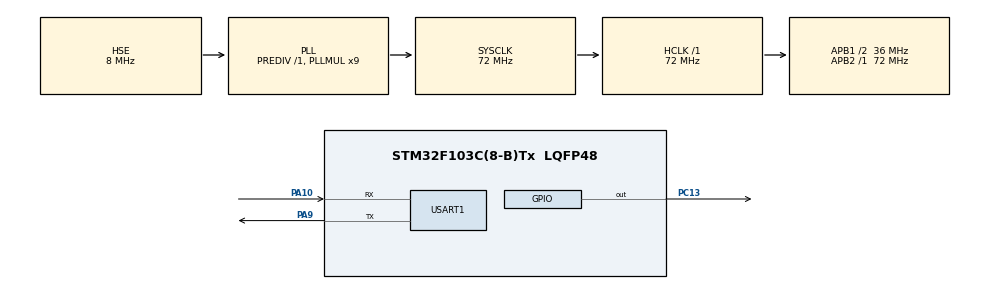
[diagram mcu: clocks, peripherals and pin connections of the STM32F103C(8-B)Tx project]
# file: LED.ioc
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Dma.Request0=USART1_TX
Dma.Request1=USART1_RX
Dma.USART1_RX.1.Direction=DMA_PERIPH_TO_MEMORY
Dma.USART1_RX.1.Instance=DMA1_Channel5
Dma.USART1_RX.1.MemDataAlignment=DMA_MDATAALIGN_BYTE
Dma.USART1_RX.1.MemInc=DMA_MINC_ENABLE
Dma.USART1_RX.1.Mode=DMA_NORMAL
Dma.USART1_RX.1.PeriphDataAlignment=DMA_PDATAALIGN_BYTE
Dma.USART1_RX.1.PeriphInc=DMA_PINC_DISABLE
Dma.USART1_RX.1.Priority=DMA_PRIORITY_LOW
Dma.USART1_TX.0.Direction=DMA_MEMORY_TO_PERIPH
Dma.USART1_TX.0.Instance=DMA1_Channel4
Dma.USART1_TX.0.MemDataAlignment=DMA_MDATAALIGN_BYTE
Dma.USART1_TX.0.MemInc=DMA_MINC_ENABLE
Dma.USART1_TX.0.Mode=DMA_NORMAL
Dma.USART1_TX.0.PeriphDataAlignment=DMA_PDATAALIGN_BYTE
Dma.USART1_TX.0.PeriphInc=DMA_PINC_DISABLE
Dma.USART1_TX.0.Priority=DMA_PRIORITY_LOW
Mcu.Family=STM32F1
Mcu.Name=STM32F103C(8-B)Tx
Mcu.Package=LQFP48
NVIC.DMA1_Channel4_IRQn=true\:0\:0\:false\:false\:true\:false
NVIC.DMA1_Channel5_IRQn=true\:0\:0\:false\:false\:true\:false
NVIC.PriorityGroup=NVIC_PRIORITYGROUP_4
NVIC.TIM1_UP_IRQn=true\:0\:0\:false\:false\:true\:true
NVIC.USART1_IRQn=true\:0\:0\:false\:false\:true\:true
PA10.Mode=Asynchronous
PA10.Signal=USART1_RX
PA13.Mode=Serial_Wire
PA13.Signal=SYS_JTMS-SWDIO
PA14.Mode=Serial_Wire
PA14.Signal=SYS_JTCK-SWCLK
PA9.Mode=Asynchronous
PA9.Signal=USART1_TX
PC13-TAMPER-RTC.Signal=GPIO_Output
PD0-OSC_IN.Mode=HSE-External-Oscillator
PD0-OSC_IN.Signal=RCC_OSC_IN
PD1-OSC_OUT.Mode=HSE-External-Oscillator
PD1-OSC_OUT.Signal=RCC_OSC_OUT
ProjectManager.HeapSize=0x200
ProjectManager.StackSize=0x400
ProjectManager.TargetToolchain=MDK-ARM V5
RCC.AHBFreq_Value=72000000
RCC.APB1CLKDivider=RCC_HCLK_DIV2
RCC.APB1Freq_Value=36000000
RCC.APB1TimFreq_Value=72000000
RCC.APB2Freq_Value=72000000
RCC.APB2TimFreq_Value=72000000
RCC.HCLKFreq_Value=72000000
RCC.PLLMUL=RCC_PLL_MUL9
RCC.PLLSourceVirtual=RCC_PLLSOURCE_HSE
RCC.SYSCLKFreq_VALUE=72000000
RCC.SYSCLKSource=RCC_SYSCLKSOURCE_PLLCLK
RCC.USBFreq_Value=72000000
TIM1.AutoReloadPreload=TIM_AUTORELOAD_PRELOAD_ENABLE
TIM1.Period=5000-1
TIM1.Prescaler=7200-1
USART1.VirtualMode=VM_ASYNC
VP_TIM1_VS_ClockSourceINT.Mode=Internal
board=custom

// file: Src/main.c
/**
  ******************************************************************************
  * @file           : main.c
  * @brief          : Main program body
  ******************************************************************************
  ** This notice applies to any and all portions of this file
  * that are not between comment pairs USER CODE BEGIN and
  * USER CODE END. Other portions of this file, whether
  * inserted by the user or by software development tools
  * are owned by their respective copyright owners.
  *
  * COPYRIGHT(c) 2018 STMicroelectronics
  *
  * Redistribution and use in source and binary forms, with or without modification,
  * are permitted provided that the following conditions are met:
  *   1. Redistributions of source code must retain the above copyright notice,
  *      this list of conditions and the following disclaimer.
  *   2. Redistributions in binary form must reproduce the above copyright notice,
  *      this list of conditions and the following disclaimer in the documentation
  *      and/or other materials provided with the distribution.
  *   3. Neither the name of STMicroelectronics nor the names of its contributors
  *      may be used to endorse or promote products derived from this software
  *      without specific prior written permission.
  *
  * THIS SOFTWARE IS PROVIDED BY THE COPYRIGHT HOLDERS AND CONTRIBUTORS "AS IS"
  * AND ANY EXPRESS OR IMPLIED WARRANTIES, INCLUDING, BUT NOT LIMITED TO, THE
  * IMPLIED WARRANTIES OF MERCHANTABILITY AND FITNESS FOR A PARTICULAR PURPOSE ARE
  * DISCLAIMED. IN NO EVENT SHALL THE COPYRIGHT HOLDER OR CONTRIBUTORS BE LIABLE
  * FOR ANY DIRECT, INDIRECT, INCIDENTAL, SPECIAL, EXEMPLARY, OR CONSEQUENTIAL
  * DAMAGES (INCLUDING, BUT NOT LIMITED TO, PROCUREMENT OF SUBSTITUTE GOODS OR
  * SERVICES; LOSS OF USE, DATA, OR PROFITS; OR BUSINESS INTERRUPTION) HOWEVER
  * CAUSED AND ON ANY THEORY OF LIABILITY, WHETHER IN CONTRACT, STRICT LIABILITY,
  * OR TORT (INCLUDING NEGLIGENCE OR OTHERWISE) ARISING IN ANY WAY OUT OF THE USE
  * OF THIS SOFTWARE, EVEN IF ADVISED OF THE POSSIBILITY OF SUCH DAMAGE.
  *
  ******************************************************************************
  */
#include "main.h"
#include "stm32f1xx_hal.h"
#include "string.h"

TIM_HandleTypeDef htim1;

UART_HandleTypeDef huart1;
DMA_HandleTypeDef hdma_usart1_tx;
DMA_HandleTypeDef hdma_usart1_rx;

/* USER CODE BEGIN PV */
/* Private variables ---------------------------------------------------------*/
#ifdef __GNUC__
/* With GCC/RAISONANCE, small printf (option LD Linker->Libraries->Small printf
   set to 'Yes') calls __io_putchar() */
#define PUTCHAR_PROTOTYPE int __io_putchar(int ch)
#else
#define PUTCHAR_PROTOTYPE int fputc(int ch, FILE *f)
#endif /* __GNUC__ */

PUTCHAR_PROTOTYPE
{
  /* Place your implementation of fputc here */
  /* e.g. write a character to the USART1 and Loop until the end of transmission */
  HAL_UART_Transmit(&huart1, (uint8_t *)&ch, 1, 0xFFFF);
  return ch;
}

/* USER CODE END PV */

void SystemClock_Config(void);
static void MX_GPIO_Init(void);
static void MX_DMA_Init(void);
static void MX_TIM1_Init(void);
static void MX_USART1_UART_Init(void);

/* USER CODE BEGIN PFP */
/* Private function prototypes -----------------------------------------------*/

/* USER CODE END PFP */

int main(void)
{

  /* MCU Configuration----------------------------------------------------------*/

  /* Reset of all peripherals, Initializes the Flash interface and the Systick. */
  HAL_Init();

  /* Configure the system clock */
  SystemClock_Config();

  /* Initialize all configured peripherals */
  MX_GPIO_Init();
  MX_DMA_Init();
  MX_TIM1_Init();
  MX_USART1_UART_Init();
  /* USER CODE BEGIN 2 */
  /*开启串口空闲中断*/
  __HAL_UART_ENABLE_IT(&huart1, UART_IT_IDLE);

    /*启动串口DMA接收*/
  HAL_UART_Receive_DMA(&huart1,rx_buffer,BUFFER_SIZE);
  HAL_TIM_Base_Start_IT(&htim1);
  printf("init ok \r\n");
  /* USER CODE END 2 */

  /* Infinite loop */
  while (1)
  {
    if(recv_end_flag ==1)
    {
        rx_len=0;
        recv_end_flag=0;
        if(strcmp((char*)rx_buffer,"LED") == 0) HAL_GPIO_TogglePin(GPIOC,GPIO_PIN_13);
//        HAL_UART_Transmit_DMA(&huart1,rx_buffer,rx_len);
//        HAL_UART_Receive_DMA(&huart1,rx_buffer,BUFFER_SIZE);
    }
  }

}

void SystemClock_Config(void)
{

  RCC_OscInitTypeDef RCC_OscInitStruct;
  RCC_ClkInitTypeDef RCC_ClkInitStruct;

    /**Initializes the CPU, AHB and APB busses clocks
    */
  RCC_OscInitStruct.OscillatorType = RCC_OSCILLATORTYPE_HSE;
  RCC_OscInitStruct.HSEState = RCC_HSE_ON;
  RCC_OscInitStruct.HSEPredivValue = RCC_HSE_PREDIV_DIV1;
  RCC_OscInitStruct.HSIState = RCC_HSI_ON;
  RCC_OscInitStruct.PLL.PLLState = RCC_PLL_ON;
  RCC_OscInitStruct.PLL.PLLSource = RCC_PLLSOURCE_HSE;
  RCC_OscInitStruct.PLL.PLLMUL = RCC_PLL_MUL9;
  if (HAL_RCC_OscConfig(&RCC_OscInitStruct) != HAL_OK)
  {
    _Error_Handler(__FILE__, __LINE__);
  }

    /**Initializes the CPU, AHB and APB busses clocks
    */
  RCC_ClkInitStruct.ClockType = RCC_CLOCKTYPE_HCLK|RCC_CLOCKTYPE_SYSCLK
                              |RCC_CLOCKTYPE_PCLK1|RCC_CLOCKTYPE_PCLK2;
  RCC_ClkInitStruct.SYSCLKSource = RCC_SYSCLKSOURCE_PLLCLK;
  RCC_ClkInitStruct.AHBCLKDivider = RCC_SYSCLK_DIV1;
  RCC_ClkInitStruct.APB1CLKDivider = RCC_HCLK_DIV2;
  RCC_ClkInitStruct.APB2CLKDivider = RCC_HCLK_DIV1;

  if (HAL_RCC_ClockConfig(&RCC_ClkInitStruct, FLASH_LATENCY_2) != HAL_OK)
  {
    _Error_Handler(__FILE__, __LINE__);
  }

    /**Configure the Systick interrupt time
    */
  HAL_SYSTICK_Config(HAL_RCC_GetHCLKFreq()/1000);

    /**Configure the Systick
    */
  HAL_SYSTICK_CLKSourceConfig(SYSTICK_CLKSOURCE_HCLK);

  /* SysTick_IRQn interrupt configuration */
  HAL_NVIC_SetPriority(SysTick_IRQn, 0, 0);
}

/* TIM1 init function */
static void MX_TIM1_Init(void)
{

  TIM_ClockConfigTypeDef sClockSourceConfig;
  TIM_MasterConfigTypeDef sMasterConfig;

  htim1.Instance = TIM1;
  htim1.Init.Prescaler = 7200-1;
  htim1.Init.CounterMode = TIM_COUNTERMODE_UP;
  htim1.Init.Period = 5000-1;
  htim1.Init.ClockDivision = TIM_CLOCKDIVISION_DIV1;
  htim1.Init.RepetitionCounter = 0;
  htim1.Init.AutoReloadPreload = TIM_AUTORELOAD_PRELOAD_ENABLE;
  if (HAL_TIM_Base_Init(&htim1) != HAL_OK)
  {
    _Error_Handler(__FILE__, __LINE__);
  }

  sClockSourceConfig.ClockSource = TIM_CLOCKSOURCE_INTERNAL;
  if (HAL_TIM_ConfigClockSource(&htim1, &sClockSourceConfig) != HAL_OK)
  {
    _Error_Handler(__FILE__, __LINE__);
  }

  sMasterConfig.MasterOutputTrigger = TIM_TRGO_RESET;
  sMasterConfig.MasterSlaveMode = TIM_MASTERSLAVEMODE_DISABLE;
  if (HAL_TIMEx_MasterConfigSynchronization(&htim1, &sMasterConfig) != HAL_OK)
  {
    _Error_Handler(__FILE__, __LINE__);
  }

}

/* USART1 init function */
static void MX_USART1_UART_Init(void)
{

  huart1.Instance = USART1;
  huart1.Init.BaudRate = 115200;
  huart1.Init.WordLength = UART_WORDLENGTH_8B;
  huart1.Init.StopBits = UART_STOPBITS_1;
  huart1.Init.Parity = UART_PARITY_NONE;
  huart1.Init.Mode = UART_MODE_TX_RX;
  huart1.Init.HwFlowCtl = UART_HWCONTROL_NONE;
  huart1.Init.OverSampling = UART_OVERSAMPLING_16;
  if (HAL_UART_Init(&huart1) != HAL_OK)
  {
    _Error_Handler(__FILE__, __LINE__);
  }

}

static void MX_DMA_Init(void)
{
  /* DMA controller clock enable */
  __HAL_RCC_DMA1_CLK_ENABLE();

  /* DMA interrupt init */
  /* DMA1_Channel4_IRQn interrupt configuration */
  HAL_NVIC_SetPriority(DMA1_Channel4_IRQn, 0, 0);
  HAL_NVIC_EnableIRQ(DMA1_Channel4_IRQn);
  /* DMA1_Channel5_IRQn interrupt configuration */
  HAL_NVIC_SetPriority(DMA1_Channel5_IRQn, 0, 0);
  HAL_NVIC_EnableIRQ(DMA1_Channel5_IRQn);

}

/** Configure pins as
        * Analog
        * Input
        * Output
        * EVENT_OUT
        * EXTI
*/
static void MX_GPIO_Init(void)
{

  GPIO_InitTypeDef GPIO_InitStruct;

  /* GPIO Ports Clock Enable */
  __HAL_RCC_GPIOC_CLK_ENABLE();
  __HAL_RCC_GPIOD_CLK_ENABLE();
  __HAL_RCC_GPIOA_CLK_ENABLE();

  /*Configure GPIO pin Output Level */
  HAL_GPIO_WritePin(GPIOC, GPIO_PIN_13, GPIO_PIN_RESET);

  /*Configure GPIO pin : PC13 */
  GPIO_InitStruct.Pin = GPIO_PIN_13;
  GPIO_InitStruct.Mode = GPIO_MODE_OUTPUT_PP;
  GPIO_InitStruct.Pull = GPIO_NOPULL;
  GPIO_InitStruct.Speed = GPIO_SPEED_FREQ_LOW;
  HAL_GPIO_Init(GPIOC, &GPIO_InitStruct);

}

/* USER CODE BEGIN 4 */
void HAL_TIM_PeriodElapsedCallback(TIM_HandleTypeDef *htim)
{
    static int i = 0;
    if (htim->Instance == TIM1)
    {
//        if(++i == 2)
//        {
//            i = 0;
//            HAL_GPIO_TogglePin(GPIOC,GPIO_PIN_13);
//        }
    }
}

//void HAL_UART_RxCpltCallback(UART_HandleTypeDef *huart)
//{
//   uint32_t tmp_flag = 0;
//   uint32_t temp;
//	if(huart==&huart1)
//	{
//   tmp_flag =  __HAL_UART_GET_FLAG(&huart1,UART_FLAG_IDLE);
//    if((tmp_flag != RESET)){
//
//        __HAL_UART_CLEAR_IDLEFLAG(&huart1);
//
//        /* 读取串口状态寄存器（芯片型号不同，寄存器名称可能需要修改） */
//        temp = huart1.Instance->SR;
//        /* 读取串口数据寄存器（芯片型号不同，寄存器名称可能需要修改） */
//        temp = huart1.Instance->DR;
//        HAL_UART_DMAStop(&huart1);
//        /* 读取DMA剩余传输数量（芯片型号不同，寄存器名称可能需要修改） */
//        temp  = hdma_usart1_rx.Instance->CNDTR;
//        rx_len =  BUFFER_SIZE - temp;
//        recv_end_flag = 1;
//    }
//	}
//}

//git test
/* USER CODE END 4 */

void _Error_Handler(char *file, int line)
{
  while(1)
  {
  }
}

/************************ (C) COPYRIGHT STMicroelectronics *****END OF FILE****/
